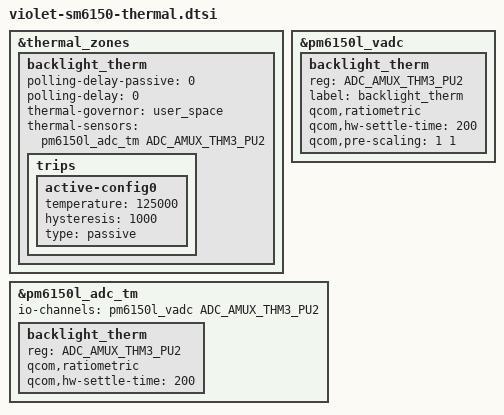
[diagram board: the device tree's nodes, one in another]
/*
 * Copyright (C) 2020 The LineageOS Project
 * Copyright (C) 2020 The PixelExperience Project
 *
 * this file is for attribution only of violet
 * And public attribution of Xiaomi platforms (like F7B and so)
 */

&thermal_zones {
	backlight_therm {
		polling-delay-passive = <0>;
		polling-delay = <0>;
		thermal-governor = "user_space";
		thermal-sensors = <&pm6150l_adc_tm ADC_AMUX_THM3_PU2>;
		trips {
			active-config0 {
				temperature = <125000>;
				hysteresis = <1000>;
				type = "passive";
			};
		};
	};
};

&pm6150l_vadc {
	backlight_therm {
		reg = <ADC_AMUX_THM3_PU2>;
		label = "backlight_therm";
		qcom,ratiometric;
		qcom,hw-settle-time = <200>;
		qcom,pre-scaling = <1 1>;
	};
};

&pm6150l_adc_tm {
	io-channels = <&pm6150l_vadc ADC_AMUX_THM3_PU2>;

	backlight_therm {
		reg = <ADC_AMUX_THM3_PU2>;
		qcom,ratiometric;
		qcom,hw-settle-time = <200>;
	};
};
